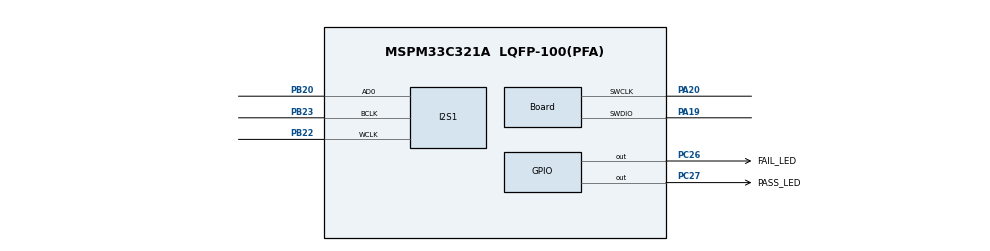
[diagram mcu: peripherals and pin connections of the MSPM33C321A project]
//@cliArgs --device "MSPM33C321A" --package "LQFP-100(PFA)" --part "Default"
//@v2CliArgs --device "MSPM33C321A" --package "LQFP-100(PFA)"
// @cliArgs --board /ti/boards/LP_MSPM33C321A --rtos nortos

/**
 * Import the modules used in this configuration.
 */
const GPIO  = scripting.addModule("/ti/driverlib/GPIO", {}, false);
const GPIO1 = GPIO.addInstance();
const I2S   = scripting.addModule("/ti/driverlib/I2S", {}, false);
const I2S1  = I2S.addInstance();

/**
 * Write custom configuration values to the imported modules.
 */
GPIO1.$name                               = "GPIO_LEDS";
GPIO1.associatedPins.create(2);
GPIO1.associatedPins[0].$name             = "PASS_LED";
GPIO1.associatedPins[0].launchPadShortcut = "LED2GreenEn";
GPIO1.associatedPins[0].pin.$assign       = "PC27";
GPIO1.associatedPins[1].$name             = "FAIL_LED";
GPIO1.associatedPins[1].launchPadShortcut = "LED2RedEn";
GPIO1.associatedPins[1].pin.$assign       = "PC26";

const Board                       = scripting.addModule("/ti/driverlib/Board", {}, false);
Board.peripheral.$assign          = "DEBUGSS";
Board.peripheral.swclkPin.$assign = "PA20";
Board.peripheral.swdioPin.$assign = "PA19";

I2S1.$name                      = "I2S_0";
I2S1.phase                      = "DUAL";
I2S1.wclkInvert                 = true;
I2S1.sampleWordLength           = 16;
I2S1.dataDelay                  = "ONE";
I2S1.dataPin0Enable             = true;
I2S1.dataPin0Direction          = "OUTPUT";
I2S1.wordBaudClockSource        = "INTERNAL";
I2S1.wclkPhase                  = "DUAL";
I2S1.wclkDivider                = 16;
I2S1.bclkDivider                = 23;
I2S1.txFIFOThreshold            = "EMPTY";
I2S1.rxFIFOThreshold            = "ONE_ENTRY";
I2S1.samplingEdge               = "POS";
I2S1.emptySlotOutput            = "TRISTATE";
I2S1.peripheral.$assign         = "I2S1";
I2S1.peripheral.AD0Pin.$assign  = "PB20";
I2S1.peripheral.BCLKPin.$assign = "PB23";
I2S1.peripheral.WCLKPin.$assign = "PB22";

const SYSCTL              = scripting.addModule("/ti/driverlib/SYSCTL", {}, false);
SYSCTL.peripheral.$assign = "SYSCTL";

const ProjectConfig              = scripting.addModule("/ti/project_config/ProjectConfig", {}, false);
ProjectConfig.migrationCondition = true;
ProjectConfig.genLinker  = true;
ProjectConfig.genStartup = true;
ProjectConfig.genOpts    = true;
ProjectConfig.genLibs    = true;
